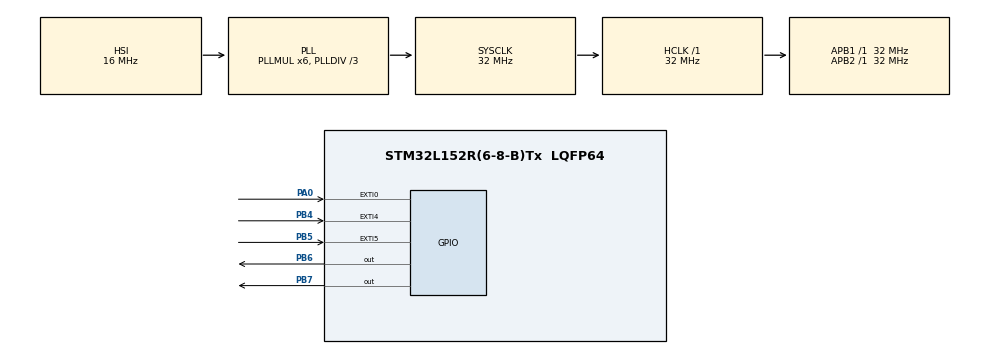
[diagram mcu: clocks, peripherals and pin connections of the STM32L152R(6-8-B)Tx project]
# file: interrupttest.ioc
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Mcu.Family=STM32L1
Mcu.Name=STM32L152R(6-8-B)Tx
Mcu.Package=LQFP64
NVIC.PriorityGroup=NVIC_PRIORITYGROUP_4
PA0-WKUP1.Signal=GPXTI0
PB4.Signal=GPXTI4
PB5.Signal=GPXTI5
PB6.Signal=GPIO_Output
PB7.Signal=GPIO_Output
ProjectManager.TargetToolchain=MDK-ARM V5
RCC.AHBFreq_Value=32000000
RCC.APB1Freq_Value=32000000
RCC.APB1TimFreq_Value=32000000
RCC.APB2Freq_Value=32000000
RCC.APB2TimFreq_Value=32000000
RCC.HCLKFreq_Value=32000000
RCC.HSE_VALUE=24000000
RCC.HSI_VALUE=16000000
RCC.LSE_VALUE=32768
RCC.MSI_VALUE=2097000
RCC.PLLDIV=RCC_PLL_DIV3
RCC.PLLMUL=RCC_PLL_MUL6
RCC.SYSCLKFreq_VALUE=32000000
RCC.SYSCLKSource=RCC_SYSCLKSOURCE_PLLCLK
RCC.USBOutput=48000000
RCC.VCOOutputFreq_Value=96000000
TIM2.Prescaler=32000
VP_TIM2_VS_ClockSourceINT.Mode=Internal
board=interrupttest

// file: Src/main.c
/**
  ******************************************************************************
  * File Name          : main.c
  * Description        : Main program body
  ******************************************************************************
  *
  * COPYRIGHT(c) 2015 STMicroelectronics
  *
  * Redistribution and use in source and binary forms, with or without modification,
  * are permitted provided that the following conditions are met:
  *   1. Redistributions of source code must retain the above copyright notice,
  *      this list of conditions and the following disclaimer.
  *   2. Redistributions in binary form must reproduce the above copyright notice,
  *      this list of conditions and the following disclaimer in the documentation
  *      and/or other materials provided with the distribution.
  *   3. Neither the name of STMicroelectronics nor the names of its contributors
  *      may be used to endorse or promote products derived from this software
  *      without specific prior written permission.
  *
  * THIS SOFTWARE IS PROVIDED BY THE COPYRIGHT HOLDERS AND CONTRIBUTORS "AS IS"
  * AND ANY EXPRESS OR IMPLIED WARRANTIES, INCLUDING, BUT NOT LIMITED TO, THE
  * IMPLIED WARRANTIES OF MERCHANTABILITY AND FITNESS FOR A PARTICULAR PURPOSE ARE
  * DISCLAIMED. IN NO EVENT SHALL THE COPYRIGHT HOLDER OR CONTRIBUTORS BE LIABLE
  * FOR ANY DIRECT, INDIRECT, INCIDENTAL, SPECIAL, EXEMPLARY, OR CONSEQUENTIAL
  * DAMAGES (INCLUDING, BUT NOT LIMITED TO, PROCUREMENT OF SUBSTITUTE GOODS OR
  * SERVICES; LOSS OF USE, DATA, OR PROFITS; OR BUSINESS INTERRUPTION) HOWEVER
  * CAUSED AND ON ANY THEORY OF LIABILITY, WHETHER IN CONTRACT, STRICT LIABILITY,
  * OR TORT (INCLUDING NEGLIGENCE OR OTHERWISE) ARISING IN ANY WAY OUT OF THE USE
  * OF THIS SOFTWARE, EVEN IF ADVISED OF THE POSSIBILITY OF SUCH DAMAGE.
  *
  ******************************************************************************
  */
#include "stm32l1xx_hal.h"

/* USER CODE BEGIN Includes */
#include "STM32L1xx.h"                  // Device header

/* USER CODE END Includes */

TIM_HandleTypeDef htim2;

/* USER CODE BEGIN PV */
/* Private variables ---------------------------------------------------------*/
uint16_t systickvalue;
uint16_t timervalue;
/* USER CODE END PV */

void SystemClock_Config(void);
static void MX_GPIO_Init(void);
static void MX_TIM2_Init(void);

/* USER CODE BEGIN PFP */
/* Private function prototypes -----------------------------------------------*/

/* USER CODE END PFP */

int main(void)
{

  /* MCU Configuration----------------------------------------------------------*/

  /* Reset of all peripherals, Initializes the Flash interface and the Systick. */
  HAL_Init();

  /* Configure the system clock */
  SystemClock_Config();

  /* Initialize all configured peripherals */
  MX_GPIO_Init();
  MX_TIM2_Init();

  /* Infinite loop */
  while (1)
  {

  }

}

/** System Clock Configuration
*/
void SystemClock_Config(void)
{

  RCC_OscInitTypeDef RCC_OscInitStruct;
  RCC_ClkInitTypeDef RCC_ClkInitStruct;

  __PWR_CLK_ENABLE();

  __HAL_PWR_VOLTAGESCALING_CONFIG(PWR_REGULATOR_VOLTAGE_SCALE1);

  RCC_OscInitStruct.OscillatorType = RCC_OSCILLATORTYPE_HSI;
  RCC_OscInitStruct.HSIState = RCC_HSI_ON;
  RCC_OscInitStruct.HSICalibrationValue = 16;
  RCC_OscInitStruct.PLL.PLLState = RCC_PLL_ON;
  RCC_OscInitStruct.PLL.PLLSource = RCC_PLLSOURCE_HSI;
  RCC_OscInitStruct.PLL.PLLMUL = RCC_PLL_MUL6;
  RCC_OscInitStruct.PLL.PLLDIV = RCC_PLL_DIV3;
  HAL_RCC_OscConfig(&RCC_OscInitStruct);

  RCC_ClkInitStruct.ClockType = RCC_CLOCKTYPE_SYSCLK;
  RCC_ClkInitStruct.SYSCLKSource = RCC_SYSCLKSOURCE_PLLCLK;
  RCC_ClkInitStruct.AHBCLKDivider = RCC_SYSCLK_DIV1;
  RCC_ClkInitStruct.APB1CLKDivider = RCC_HCLK_DIV1;
  RCC_ClkInitStruct.APB2CLKDivider = RCC_HCLK_DIV1;
  HAL_RCC_ClockConfig(&RCC_ClkInitStruct, FLASH_LATENCY_1);

  HAL_SYSTICK_Config(HAL_RCC_GetHCLKFreq()/1000);

  HAL_SYSTICK_CLKSourceConfig(SYSTICK_CLKSOURCE_HCLK);

  /* SysTick_IRQn interrupt configuration */
  HAL_NVIC_SetPriority(SysTick_IRQn, 0, 0);
}

/* TIM2 init function */
void MX_TIM2_Init(void)
{

  TIM_ClockConfigTypeDef sClockSourceConfig;
  TIM_MasterConfigTypeDef sMasterConfig;

  htim2.Instance = TIM2;
  htim2.Init.Prescaler = 32000;
  htim2.Init.CounterMode = TIM_COUNTERMODE_UP;
  htim2.Init.Period = 0;
  htim2.Init.ClockDivision = TIM_CLOCKDIVISION_DIV1;
  HAL_TIM_Base_Init(&htim2);
	htim2.Instance->CR1 |= 1<<2;
	htim2.Instance->CR1 |= 1<<1;
	htim2.Instance->CR1 |= 1<<0;
	htim2.Instance->ARR |= 0xFFFF;

  sClockSourceConfig.ClockSource = TIM_CLOCKSOURCE_INTERNAL;
  HAL_TIM_ConfigClockSource(&htim2, &sClockSourceConfig);

  sMasterConfig.MasterOutputTrigger = TIM_TRGO_RESET;
  sMasterConfig.MasterSlaveMode = TIM_MASTERSLAVEMODE_DISABLE;
  HAL_TIMEx_MasterConfigSynchronization(&htim2, &sMasterConfig);

	 __HAL_RCC_TIM2_CLK_ENABLE();
	HAL_TIM_Base_Start(&htim2);
	htim2.Instance->EGR = 1<<0;
	htim2.Instance->SR = 0<<0;

}

/** Configure pins as
        * Analog
        * Input
        * Output
        * EVENT_OUT
        * EXTI
*/
void MX_GPIO_Init(void)
{

  GPIO_InitTypeDef GPIO_InitStruct;

  /* GPIO Ports Clock Enable */
  __GPIOA_CLK_ENABLE();
  __GPIOB_CLK_ENABLE();

  /*Configure GPIO pin : PA0 */
  GPIO_InitStruct.Pin = GPIO_PIN_0;
  GPIO_InitStruct.Mode = GPIO_MODE_IT_RISING;
  GPIO_InitStruct.Pull = GPIO_NOPULL;
  HAL_GPIO_Init(GPIOA, &GPIO_InitStruct);

	NVIC_SetPriority(EXTI0_IRQn,8);
	NVIC_EnableIRQ(EXTI0_IRQn);

  /*Configure GPIO pins : PB4 PB5 */
  GPIO_InitStruct.Pin = GPIO_PIN_4|GPIO_PIN_5;
  GPIO_InitStruct.Mode = GPIO_MODE_IT_RISING;
  GPIO_InitStruct.Pull = GPIO_NOPULL;
  HAL_GPIO_Init(GPIOB, &GPIO_InitStruct);

  /*Configure GPIO pins : PB6 PB7 */
  GPIO_InitStruct.Pin = GPIO_PIN_6|GPIO_PIN_7;
  GPIO_InitStruct.Mode = GPIO_MODE_OUTPUT_PP;
  GPIO_InitStruct.Pull = GPIO_NOPULL;
  GPIO_InitStruct.Speed = GPIO_SPEED_VERY_LOW;
  HAL_GPIO_Init(GPIOB, &GPIO_InitStruct);

//dfhalfhldfjh

}

/* USER CODE BEGIN 4 */

// external interrupt 0 handler
void EXTI0_IRQHandler(void)
{

	timervalue = __HAL_TIM_GET_COUNTER(&htim2);

	if( (EXTI->IMR & EXTI_IMR_MR0) && (EXTI->PR & EXTI_PR_PR0))
		{
			if((GPIOB ->ODR & GPIO_ODR_ODR_6) == GPIO_ODR_ODR_6)
			{
				GPIOB ->BSRR |= GPIO_BSRR_BR_6;
			}
			else
			{
				GPIOB ->BSRR |= GPIO_BSRR_BS_6;
			}
    }
		htim2.Instance->CNT = htim2.Instance->ARR;
		EXTI->PR |= EXTI_PR_PR0 ;

}

/* USER CODE END 4 */

/************************ (C) COPYRIGHT STMicroelectronics *****END OF FILE****/
